VERSION "generated by build_dbc"

NS_ :

BS_:

BU_: Vector__XXX

BO_ 0 MSG_000: 8 Vector__XXX
 SG_ Service : 0|8@1+ (1,0) [0|255] "" Vector__XXX
 SG_ PID M : 8|8@1+ (1,0) [0|255] "" Vector__XXX
 SG_ PID_F4 m244: 16|8@1+ (1,0) [0|255] "" Vector__XXX

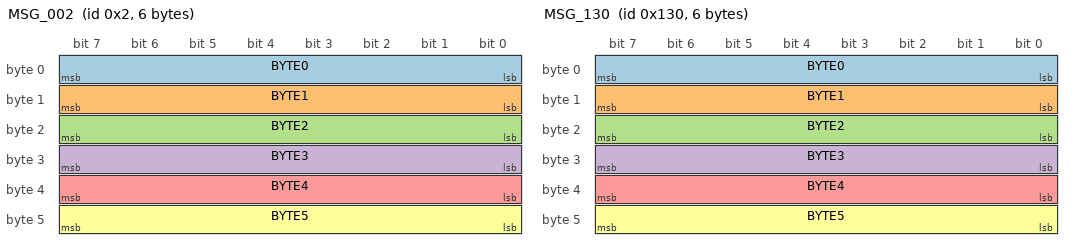
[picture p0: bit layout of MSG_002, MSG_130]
BO_ 2 MSG_002: 6 Vector__XXX
 SG_ BYTE0 : 0|8@1+ (1,0) [0|255] "" Vector__XXX
 SG_ BYTE1 : 8|8@1+ (1,0) [0|255] "" Vector__XXX
 SG_ BYTE2 : 16|8@1+ (1,0) [0|255] "" Vector__XXX
 SG_ BYTE3 : 24|8@1+ (1,0) [0|255] "" Vector__XXX
 SG_ BYTE4 : 32|8@1+ (1,0) [0|255] "" Vector__XXX
 SG_ BYTE5 : 40|8@1+ (1,0) [0|255] "" Vector__XXX

BO_ 153 MSG_099: 1 Vector__XXX
 SG_ BYTE0 : 0|8@1+ (1,0) [0|255] "" Vector__XXX

BO_ 304 MSG_130: 6 Vector__XXX
 SG_ BYTE0 : 0|8@1+ (1,0) [0|255] "" Vector__XXX
 SG_ BYTE1 : 8|8@1+ (1,0) [0|255] "" Vector__XXX
 SG_ BYTE2 : 16|8@1+ (1,0) [0|255] "" Vector__XXX
 SG_ BYTE3 : 24|8@1+ (1,0) [0|255] "" Vector__XXX
 SG_ BYTE4 : 32|8@1+ (1,0) [0|255] "" Vector__XXX
 SG_ BYTE5 : 40|8@1+ (1,0) [0|255] "" Vector__XXX

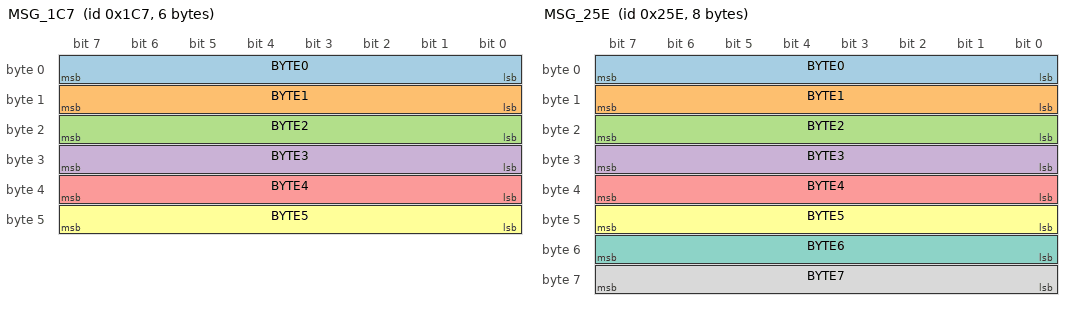
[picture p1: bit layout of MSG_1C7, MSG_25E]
BO_ 455 MSG_1C7: 6 Vector__XXX
 SG_ BYTE0 : 0|8@1+ (1,0) [0|255] "" Vector__XXX
 SG_ BYTE1 : 8|8@1+ (1,0) [0|255] "" Vector__XXX
 SG_ BYTE2 : 16|8@1+ (1,0) [0|255] "" Vector__XXX
 SG_ BYTE3 : 24|8@1+ (1,0) [0|255] "" Vector__XXX
 SG_ BYTE4 : 32|8@1+ (1,0) [0|255] "" Vector__XXX
 SG_ BYTE5 : 40|8@1+ (1,0) [0|255] "" Vector__XXX

BO_ 606 MSG_25E: 8 Vector__XXX
 SG_ BYTE0 : 0|8@1+ (1,0) [0|255] "" Vector__XXX
 SG_ BYTE1 : 8|8@1+ (1,0) [0|255] "" Vector__XXX
 SG_ BYTE2 : 16|8@1+ (1,0) [0|255] "" Vector__XXX
 SG_ BYTE3 : 24|8@1+ (1,0) [0|255] "" Vector__XXX
 SG_ BYTE4 : 32|8@1+ (1,0) [0|255] "" Vector__XXX
 SG_ BYTE5 : 40|8@1+ (1,0) [0|255] "" Vector__XXX
 SG_ BYTE6 : 48|8@1+ (1,0) [0|255] "" Vector__XXX
 SG_ BYTE7 : 56|8@1+ (1,0) [0|255] "" Vector__XXX

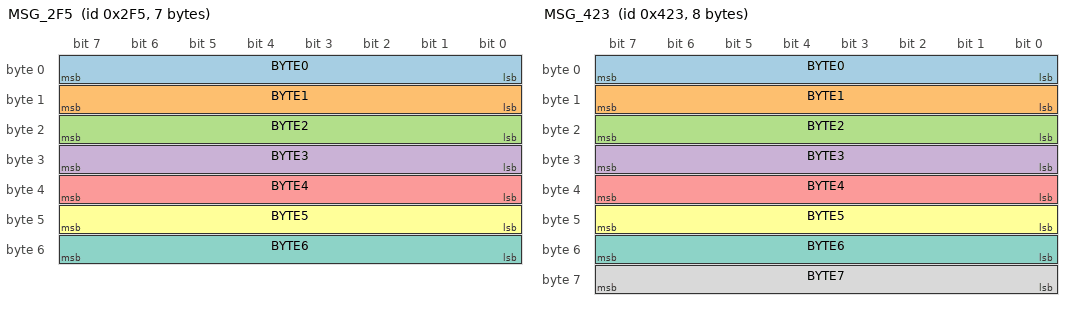
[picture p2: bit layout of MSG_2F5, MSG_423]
BO_ 757 MSG_2F5: 7 Vector__XXX
 SG_ BYTE0 : 0|8@1+ (1,0) [0|255] "" Vector__XXX
 SG_ BYTE1 : 8|8@1+ (1,0) [0|255] "" Vector__XXX
 SG_ BYTE2 : 16|8@1+ (1,0) [0|255] "" Vector__XXX
 SG_ BYTE3 : 24|8@1+ (1,0) [0|255] "" Vector__XXX
 SG_ BYTE4 : 32|8@1+ (1,0) [0|255] "" Vector__XXX
 SG_ BYTE5 : 40|8@1+ (1,0) [0|255] "" Vector__XXX
 SG_ BYTE6 : 48|8@1+ (1,0) [0|255] "" Vector__XXX

BO_ 1059 MSG_423: 8 Vector__XXX
 SG_ BYTE0 : 0|8@1+ (1,0) [0|255] "" Vector__XXX
 SG_ BYTE1 : 8|8@1+ (1,0) [0|255] "" Vector__XXX
 SG_ BYTE2 : 16|8@1+ (1,0) [0|255] "" Vector__XXX
 SG_ BYTE3 : 24|8@1+ (1,0) [0|255] "" Vector__XXX
 SG_ BYTE4 : 32|8@1+ (1,0) [0|255] "" Vector__XXX
 SG_ BYTE5 : 40|8@1+ (1,0) [0|255] "" Vector__XXX
 SG_ BYTE6 : 48|8@1+ (1,0) [0|255] "" Vector__XXX
 SG_ BYTE7 : 56|8@1+ (1,0) [0|255] "" Vector__XXX

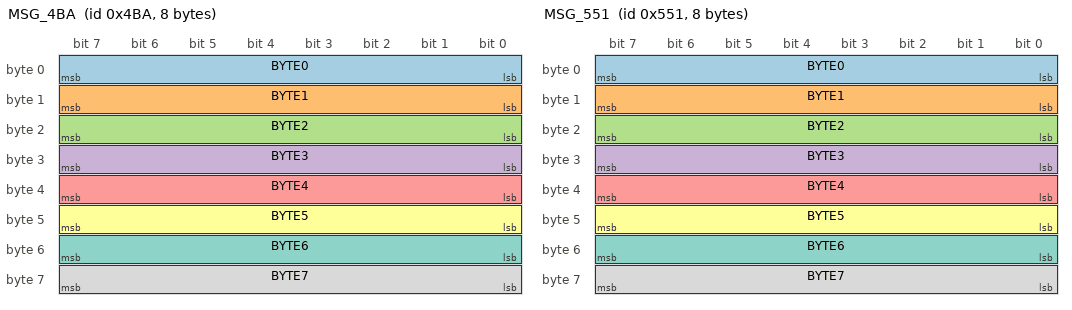
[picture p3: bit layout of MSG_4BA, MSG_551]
BO_ 1210 MSG_4BA: 8 Vector__XXX
 SG_ BYTE0 : 0|8@1+ (1,0) [0|255] "" Vector__XXX
 SG_ BYTE1 : 8|8@1+ (1,0) [0|255] "" Vector__XXX
 SG_ BYTE2 : 16|8@1+ (1,0) [0|255] "" Vector__XXX
 SG_ BYTE3 : 24|8@1+ (1,0) [0|255] "" Vector__XXX
 SG_ BYTE4 : 32|8@1+ (1,0) [0|255] "" Vector__XXX
 SG_ BYTE5 : 40|8@1+ (1,0) [0|255] "" Vector__XXX
 SG_ BYTE6 : 48|8@1+ (1,0) [0|255] "" Vector__XXX
 SG_ BYTE7 : 56|8@1+ (1,0) [0|255] "" Vector__XXX

BO_ 1361 MSG_551: 8 Vector__XXX
 SG_ BYTE0 : 0|8@1+ (1,0) [0|255] "" Vector__XXX
 SG_ BYTE1 : 8|8@1+ (1,0) [0|255] "" Vector__XXX
 SG_ BYTE2 : 16|8@1+ (1,0) [0|255] "" Vector__XXX
 SG_ BYTE3 : 24|8@1+ (1,0) [0|255] "" Vector__XXX
 SG_ BYTE4 : 32|8@1+ (1,0) [0|255] "" Vector__XXX
 SG_ BYTE5 : 40|8@1+ (1,0) [0|255] "" Vector__XXX
 SG_ BYTE6 : 48|8@1+ (1,0) [0|255] "" Vector__XXX
 SG_ BYTE7 : 56|8@1+ (1,0) [0|255] "" Vector__XXX

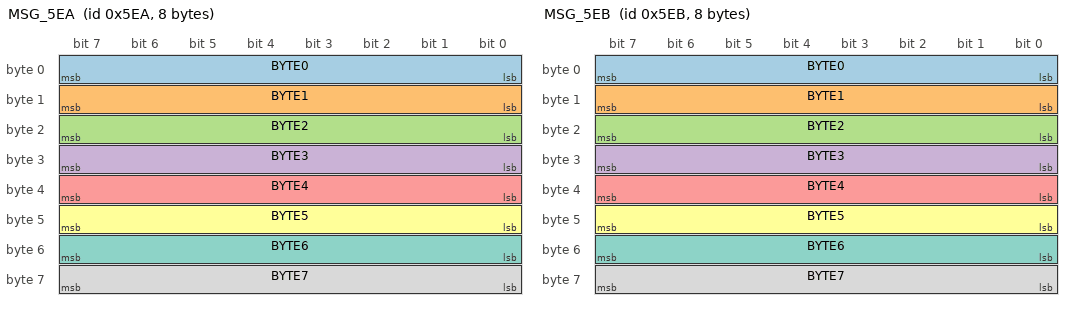
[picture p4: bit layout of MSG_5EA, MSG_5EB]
BO_ 1514 MSG_5EA: 8 Vector__XXX
 SG_ BYTE0 : 0|8@1+ (1,0) [0|255] "" Vector__XXX
 SG_ BYTE1 : 8|8@1+ (1,0) [0|255] "" Vector__XXX
 SG_ BYTE2 : 16|8@1+ (1,0) [0|255] "" Vector__XXX
 SG_ BYTE3 : 24|8@1+ (1,0) [0|255] "" Vector__XXX
 SG_ BYTE4 : 32|8@1+ (1,0) [0|255] "" Vector__XXX
 SG_ BYTE5 : 40|8@1+ (1,0) [0|255] "" Vector__XXX
 SG_ BYTE6 : 48|8@1+ (1,0) [0|255] "" Vector__XXX
 SG_ BYTE7 : 56|8@1+ (1,0) [0|255] "" Vector__XXX

BO_ 1515 MSG_5EB: 8 Vector__XXX
 SG_ BYTE0 : 0|8@1+ (1,0) [0|255] "" Vector__XXX
 SG_ BYTE1 : 8|8@1+ (1,0) [0|255] "" Vector__XXX
 SG_ BYTE2 : 16|8@1+ (1,0) [0|255] "" Vector__XXX
 SG_ BYTE3 : 24|8@1+ (1,0) [0|255] "" Vector__XXX
 SG_ BYTE4 : 32|8@1+ (1,0) [0|255] "" Vector__XXX
 SG_ BYTE5 : 40|8@1+ (1,0) [0|255] "" Vector__XXX
 SG_ BYTE6 : 48|8@1+ (1,0) [0|255] "" Vector__XXX
 SG_ BYTE7 : 56|8@1+ (1,0) [0|255] "" Vector__XXX

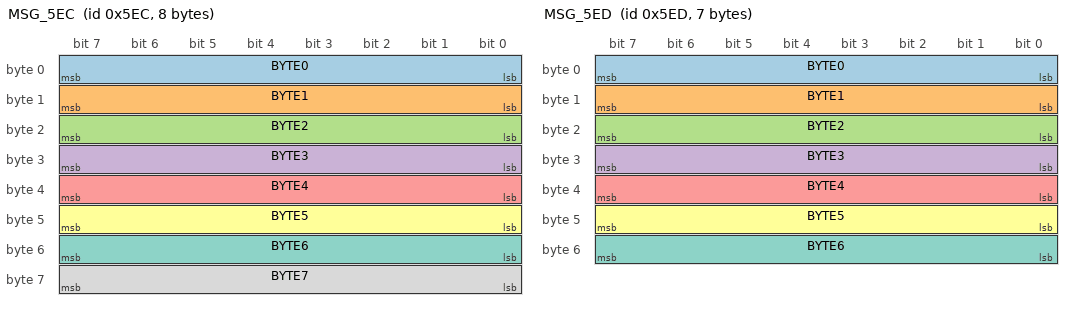
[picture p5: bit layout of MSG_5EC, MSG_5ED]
BO_ 1516 MSG_5EC: 8 Vector__XXX
 SG_ BYTE0 : 0|8@1+ (1,0) [0|255] "" Vector__XXX
 SG_ BYTE1 : 8|8@1+ (1,0) [0|255] "" Vector__XXX
 SG_ BYTE2 : 16|8@1+ (1,0) [0|255] "" Vector__XXX
 SG_ BYTE3 : 24|8@1+ (1,0) [0|255] "" Vector__XXX
 SG_ BYTE4 : 32|8@1+ (1,0) [0|255] "" Vector__XXX
 SG_ BYTE5 : 40|8@1+ (1,0) [0|255] "" Vector__XXX
 SG_ BYTE6 : 48|8@1+ (1,0) [0|255] "" Vector__XXX
 SG_ BYTE7 : 56|8@1+ (1,0) [0|255] "" Vector__XXX

BO_ 1517 MSG_5ED: 7 Vector__XXX
 SG_ BYTE0 : 0|8@1+ (1,0) [0|255] "" Vector__XXX
 SG_ BYTE1 : 8|8@1+ (1,0) [0|255] "" Vector__XXX
 SG_ BYTE2 : 16|8@1+ (1,0) [0|255] "" Vector__XXX
 SG_ BYTE3 : 24|8@1+ (1,0) [0|255] "" Vector__XXX
 SG_ BYTE4 : 32|8@1+ (1,0) [0|255] "" Vector__XXX
 SG_ BYTE5 : 40|8@1+ (1,0) [0|255] "" Vector__XXX
 SG_ BYTE6 : 48|8@1+ (1,0) [0|255] "" Vector__XXX

BO_ 1518 MSG_5EE: 1 Vector__XXX
 SG_ BYTE0 : 0|8@1+ (1,0) [0|255] "" Vector__XXX

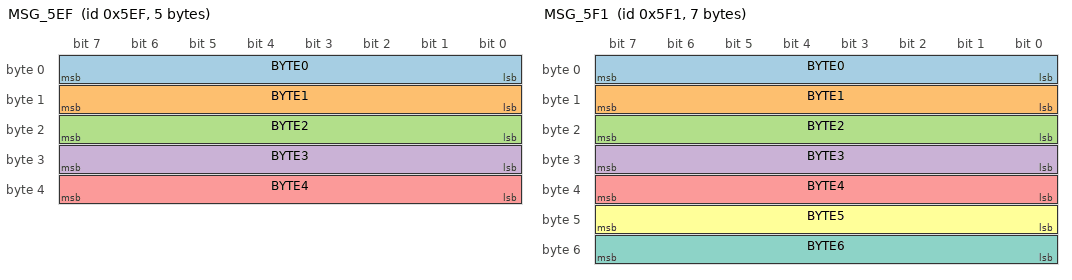
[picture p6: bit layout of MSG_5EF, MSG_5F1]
BO_ 1519 MSG_5EF: 5 Vector__XXX
 SG_ BYTE0 : 0|8@1+ (1,0) [0|255] "" Vector__XXX
 SG_ BYTE1 : 8|8@1+ (1,0) [0|255] "" Vector__XXX
 SG_ BYTE2 : 16|8@1+ (1,0) [0|255] "" Vector__XXX
 SG_ BYTE3 : 24|8@1+ (1,0) [0|255] "" Vector__XXX
 SG_ BYTE4 : 32|8@1+ (1,0) [0|255] "" Vector__XXX

BO_ 1521 MSG_5F1: 7 Vector__XXX
 SG_ BYTE0 : 0|8@1+ (1,0) [0|255] "" Vector__XXX
 SG_ BYTE1 : 8|8@1+ (1,0) [0|255] "" Vector__XXX
 SG_ BYTE2 : 16|8@1+ (1,0) [0|255] "" Vector__XXX
 SG_ BYTE3 : 24|8@1+ (1,0) [0|255] "" Vector__XXX
 SG_ BYTE4 : 32|8@1+ (1,0) [0|255] "" Vector__XXX
 SG_ BYTE5 : 40|8@1+ (1,0) [0|255] "" Vector__XXX
 SG_ BYTE6 : 48|8@1+ (1,0) [0|255] "" Vector__XXX

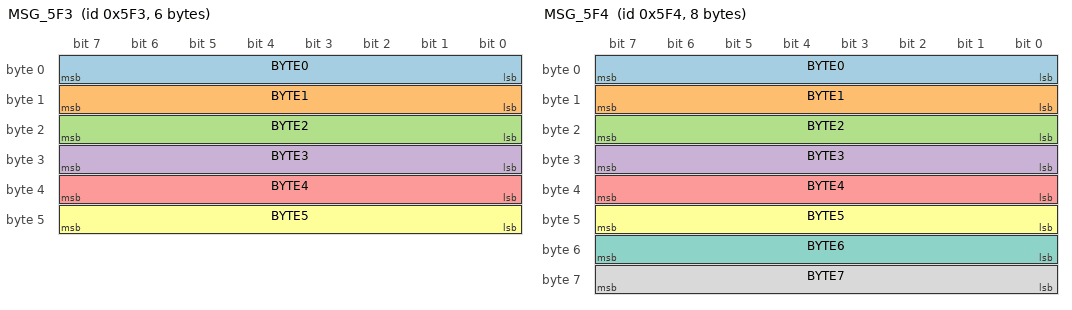
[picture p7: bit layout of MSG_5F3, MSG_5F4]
BO_ 1523 MSG_5F3: 6 Vector__XXX
 SG_ BYTE0 : 0|8@1+ (1,0) [0|255] "" Vector__XXX
 SG_ BYTE1 : 8|8@1+ (1,0) [0|255] "" Vector__XXX
 SG_ BYTE2 : 16|8@1+ (1,0) [0|255] "" Vector__XXX
 SG_ BYTE3 : 24|8@1+ (1,0) [0|255] "" Vector__XXX
 SG_ BYTE4 : 32|8@1+ (1,0) [0|255] "" Vector__XXX
 SG_ BYTE5 : 40|8@1+ (1,0) [0|255] "" Vector__XXX

BO_ 1524 MSG_5F4: 8 Vector__XXX
 SG_ BYTE0 : 0|8@1+ (1,0) [0|255] "" Vector__XXX
 SG_ BYTE1 : 8|8@1+ (1,0) [0|255] "" Vector__XXX
 SG_ BYTE2 : 16|8@1+ (1,0) [0|255] "" Vector__XXX
 SG_ BYTE3 : 24|8@1+ (1,0) [0|255] "" Vector__XXX
 SG_ BYTE4 : 32|8@1+ (1,0) [0|255] "" Vector__XXX
 SG_ BYTE5 : 40|8@1+ (1,0) [0|255] "" Vector__XXX
 SG_ BYTE6 : 48|8@1+ (1,0) [0|255] "" Vector__XXX
 SG_ BYTE7 : 56|8@1+ (1,0) [0|255] "" Vector__XXX

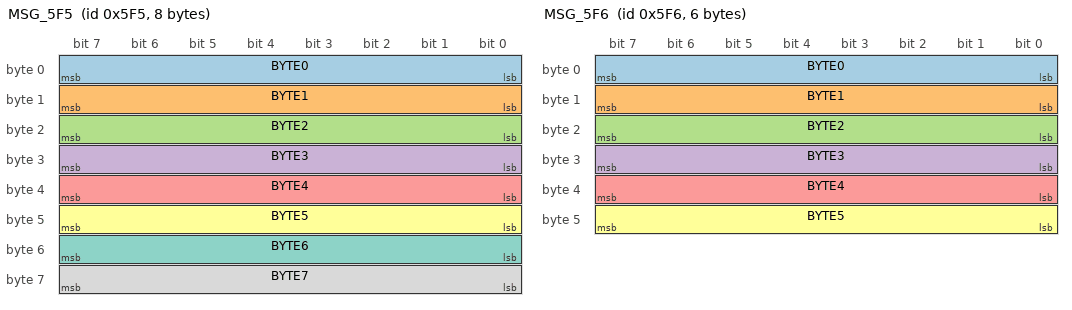
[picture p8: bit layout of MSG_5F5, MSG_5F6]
BO_ 1525 MSG_5F5: 8 Vector__XXX
 SG_ BYTE0 : 0|8@1+ (1,0) [0|255] "" Vector__XXX
 SG_ BYTE1 : 8|8@1+ (1,0) [0|255] "" Vector__XXX
 SG_ BYTE2 : 16|8@1+ (1,0) [0|255] "" Vector__XXX
 SG_ BYTE3 : 24|8@1+ (1,0) [0|255] "" Vector__XXX
 SG_ BYTE4 : 32|8@1+ (1,0) [0|255] "" Vector__XXX
 SG_ BYTE5 : 40|8@1+ (1,0) [0|255] "" Vector__XXX
 SG_ BYTE6 : 48|8@1+ (1,0) [0|255] "" Vector__XXX
 SG_ BYTE7 : 56|8@1+ (1,0) [0|255] "" Vector__XXX

BO_ 1526 MSG_5F6: 6 Vector__XXX
 SG_ BYTE0 : 0|8@1+ (1,0) [0|255] "" Vector__XXX
 SG_ BYTE1 : 8|8@1+ (1,0) [0|255] "" Vector__XXX
 SG_ BYTE2 : 16|8@1+ (1,0) [0|255] "" Vector__XXX
 SG_ BYTE3 : 24|8@1+ (1,0) [0|255] "" Vector__XXX
 SG_ BYTE4 : 32|8@1+ (1,0) [0|255] "" Vector__XXX
 SG_ BYTE5 : 40|8@1+ (1,0) [0|255] "" Vector__XXX

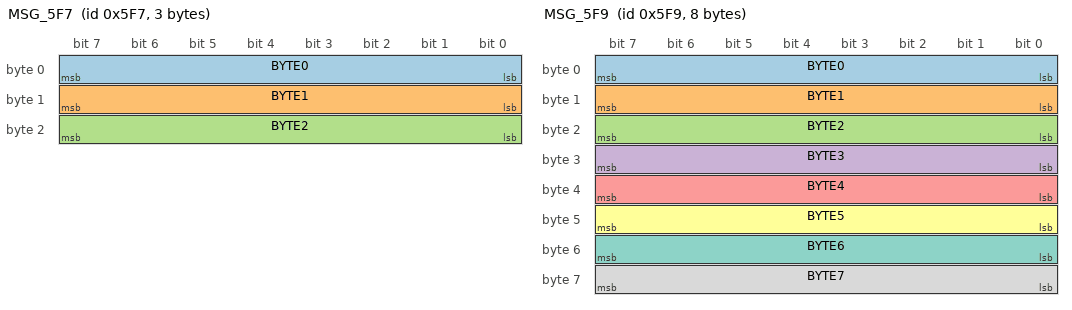
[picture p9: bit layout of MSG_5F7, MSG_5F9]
BO_ 1527 MSG_5F7: 3 Vector__XXX
 SG_ BYTE0 : 0|8@1+ (1,0) [0|255] "" Vector__XXX
 SG_ BYTE1 : 8|8@1+ (1,0) [0|255] "" Vector__XXX
 SG_ BYTE2 : 16|8@1+ (1,0) [0|255] "" Vector__XXX

BO_ 1528 MSG_5F8: 2 Vector__XXX
 SG_ BYTE0 : 0|8@1+ (1,0) [0|255] "" Vector__XXX
 SG_ BYTE1 : 8|8@1+ (1,0) [0|255] "" Vector__XXX

BO_ 1529 MSG_5F9: 8 Vector__XXX
 SG_ BYTE0 : 0|8@1+ (1,0) [0|255] "" Vector__XXX
 SG_ BYTE1 : 8|8@1+ (1,0) [0|255] "" Vector__XXX
 SG_ BYTE2 : 16|8@1+ (1,0) [0|255] "" Vector__XXX
 SG_ BYTE3 : 24|8@1+ (1,0) [0|255] "" Vector__XXX
 SG_ BYTE4 : 32|8@1+ (1,0) [0|255] "" Vector__XXX
 SG_ BYTE5 : 40|8@1+ (1,0) [0|255] "" Vector__XXX
 SG_ BYTE6 : 48|8@1+ (1,0) [0|255] "" Vector__XXX
 SG_ BYTE7 : 56|8@1+ (1,0) [0|255] "" Vector__XXX

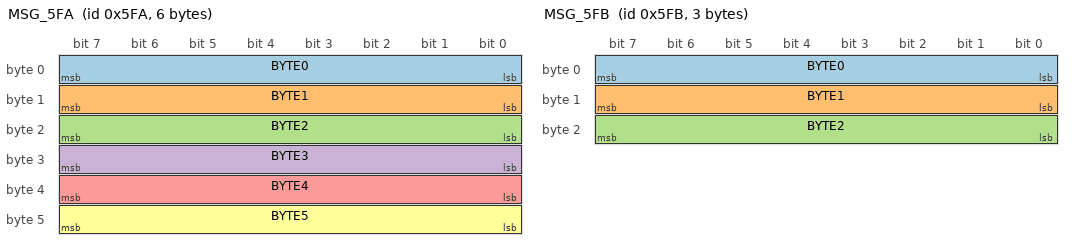
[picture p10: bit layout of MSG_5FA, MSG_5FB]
BO_ 1530 MSG_5FA: 6 Vector__XXX
 SG_ BYTE0 : 0|8@1+ (1,0) [0|255] "" Vector__XXX
 SG_ BYTE1 : 8|8@1+ (1,0) [0|255] "" Vector__XXX
 SG_ BYTE2 : 16|8@1+ (1,0) [0|255] "" Vector__XXX
 SG_ BYTE3 : 24|8@1+ (1,0) [0|255] "" Vector__XXX
 SG_ BYTE4 : 32|8@1+ (1,0) [0|255] "" Vector__XXX
 SG_ BYTE5 : 40|8@1+ (1,0) [0|255] "" Vector__XXX

BO_ 1531 MSG_5FB: 3 Vector__XXX
 SG_ BYTE0 : 0|8@1+ (1,0) [0|255] "" Vector__XXX
 SG_ BYTE1 : 8|8@1+ (1,0) [0|255] "" Vector__XXX
 SG_ BYTE2 : 16|8@1+ (1,0) [0|255] "" Vector__XXX

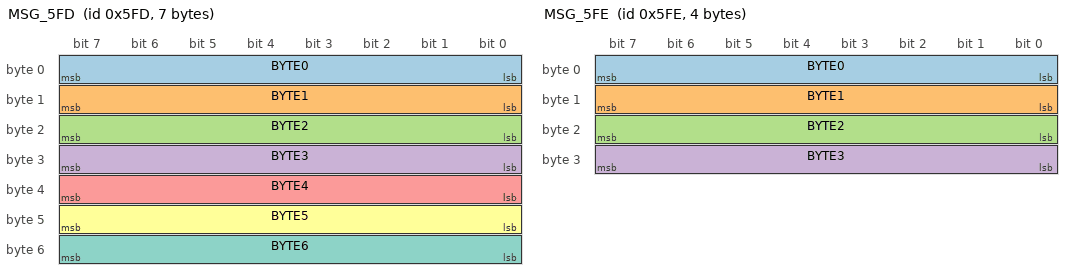
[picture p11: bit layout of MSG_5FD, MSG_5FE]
BO_ 1533 MSG_5FD: 7 Vector__XXX
 SG_ BYTE0 : 0|8@1+ (1,0) [0|255] "" Vector__XXX
 SG_ BYTE1 : 8|8@1+ (1,0) [0|255] "" Vector__XXX
 SG_ BYTE2 : 16|8@1+ (1,0) [0|255] "" Vector__XXX
 SG_ BYTE3 : 24|8@1+ (1,0) [0|255] "" Vector__XXX
 SG_ BYTE4 : 32|8@1+ (1,0) [0|255] "" Vector__XXX
 SG_ BYTE5 : 40|8@1+ (1,0) [0|255] "" Vector__XXX
 SG_ BYTE6 : 48|8@1+ (1,0) [0|255] "" Vector__XXX

BO_ 1534 MSG_5FE: 4 Vector__XXX
 SG_ BYTE0 : 0|8@1+ (1,0) [0|255] "" Vector__XXX
 SG_ BYTE1 : 8|8@1+ (1,0) [0|255] "" Vector__XXX
 SG_ BYTE2 : 16|8@1+ (1,0) [0|255] "" Vector__XXX
 SG_ BYTE3 : 24|8@1+ (1,0) [0|255] "" Vector__XXX

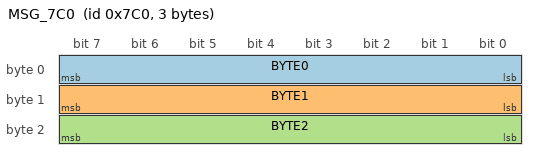
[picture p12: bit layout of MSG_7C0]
BO_ 1984 MSG_7C0: 3 Vector__XXX
 SG_ BYTE0 : 0|8@1+ (1,0) [0|255] "" Vector__XXX
 SG_ BYTE1 : 8|8@1+ (1,0) [0|255] "" Vector__XXX
 SG_ BYTE2 : 16|8@1+ (1,0) [0|255] "" Vector__XXX
